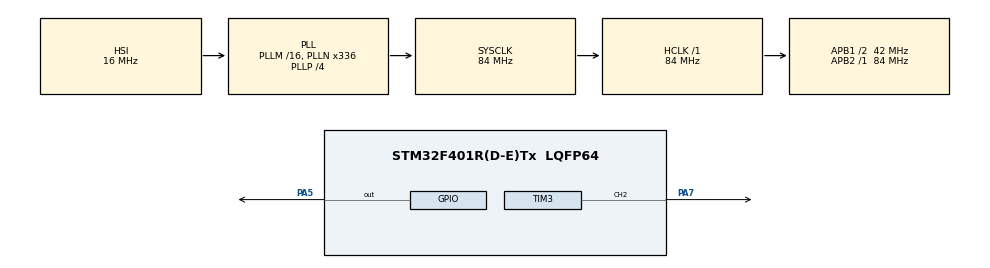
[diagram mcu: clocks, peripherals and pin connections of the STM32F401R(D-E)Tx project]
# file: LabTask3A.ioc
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Mcu.Family=STM32F4
Mcu.Name=STM32F401R(D-E)Tx
Mcu.Package=LQFP64
NVIC.PriorityGroup=NVIC_PRIORITYGROUP_4
NVIC.TIM3_IRQn=true\:0\:0\:false\:false\:true\:true\:true\:true
NVIC.TIM4_IRQn=true\:0\:0\:false\:false\:true\:true\:true\:true
PA5.Signal=GPIO_Output
PA7.Signal=S_TIM3_CH2
ProjectManager.HeapSize=0x200
ProjectManager.StackSize=0x400
ProjectManager.TargetToolchain=STM32CubeIDE
RCC.48MHZClocksFreq_Value=84000000
RCC.AHBFreq_Value=84000000
RCC.APB1CLKDivider=RCC_HCLK_DIV2
RCC.APB1Freq_Value=42000000
RCC.APB1TimFreq_Value=84000000
RCC.APB2Freq_Value=84000000
RCC.APB2TimFreq_Value=84000000
RCC.CortexFreq_Value=84000000
RCC.HCLKFreq_Value=84000000
RCC.HSE_VALUE=25000000
RCC.HSI_VALUE=16000000
RCC.LSE_VALUE=32768
RCC.PLLN=336
RCC.PLLP=RCC_PLLP_DIV4
RCC.SYSCLKFreq_VALUE=84000000
RCC.SYSCLKSource=RCC_SYSCLKSOURCE_PLLCLK
RCC.VCOOutputFreq_Value=336000000
SH.S_TIM3_CH2.0=TIM3_CH2,PWM Generation2 CH2
TIM3.AutoReloadPreload=TIM_AUTORELOAD_PRELOAD_ENABLE
TIM3.Channel-PWM\ Generation2\ CH2=TIM_CHANNEL_2
TIM3.Period=3821
TIM3.Prescaler=83
TIM3.Pulse-PWM\ Generation2\ CH2=1911
TIM4.Period=4999
TIM4.Prescaler=8399
VP_TIM3_VS_ClockSourceINT.Mode=Internal
VP_TIM4_VS_ClockSourceINT.Mode=Internal
board=custom

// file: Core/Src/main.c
/* USER CODE BEGIN Header */
/**
  ******************************************************************************
  * @file           : main.c
  * @brief          : Main program body
  ******************************************************************************
  * @attention
  *
  * Copyright (c) 2026 STMicroelectronics.
  * All rights reserved.
  *
  * This software is licensed under terms that can be found in the LICENSE file
  * in the root directory of this software component.
  * If no LICENSE file comes with this software, it is provided AS-IS.
  *
  ******************************************************************************
  */
/* USER CODE END Header */
#include "main.h"

TIM_HandleTypeDef htim3;
TIM_HandleTypeDef htim4;

/* USER CODE BEGIN PV */
uint32_t note_arr[] = {
    3821,   // C4
    3405,   // D4
    3032,   // E4
    2550    // G4
};

uint32_t duty_arr[] = {
    255,    // 10%
    1276,   // 50%
    2296    // 90%
};

volatile uint8_t note = 0;
volatile uint8_t duty = 0;
/* USER CODE END PV */

void SystemClock_Config(void);
static void MX_GPIO_Init(void);
static void MX_TIM3_Init(void);
static void MX_TIM4_Init(void);

int main(void)
{

  /* MCU Configuration--------------------------------------------------------*/

  /* Reset of all peripherals, Initializes the Flash interface and the Systick. */
  HAL_Init();

  /* Configure the system clock */
  SystemClock_Config();

  /* Initialize all configured peripherals */
  MX_GPIO_Init();
  MX_TIM3_Init();
  MX_TIM4_Init();
  /* USER CODE BEGIN 2 */

  HAL_TIM_PWM_Start(&htim3, TIM_CHANNEL_2);
  HAL_TIM_Base_Start_IT(&htim4);

  /* USER CODE END 2 */

  /* Infinite loop */
  while (1)
  {

  }
}

void SystemClock_Config(void)
{
  RCC_OscInitTypeDef RCC_OscInitStruct = {0};
  RCC_ClkInitTypeDef RCC_ClkInitStruct = {0};

  /** Configure the main internal regulator output voltage
  */
  __HAL_RCC_PWR_CLK_ENABLE();
  __HAL_PWR_VOLTAGESCALING_CONFIG(PWR_REGULATOR_VOLTAGE_SCALE2);

  /** Initializes the RCC Oscillators according to the specified parameters
  * in the RCC_OscInitTypeDef structure.
  */
  RCC_OscInitStruct.OscillatorType = RCC_OSCILLATORTYPE_HSI;
  RCC_OscInitStruct.HSIState = RCC_HSI_ON;
  RCC_OscInitStruct.HSICalibrationValue = RCC_HSICALIBRATION_DEFAULT;
  RCC_OscInitStruct.PLL.PLLState = RCC_PLL_ON;
  RCC_OscInitStruct.PLL.PLLSource = RCC_PLLSOURCE_HSI;
  RCC_OscInitStruct.PLL.PLLM = 16;
  RCC_OscInitStruct.PLL.PLLN = 336;
  RCC_OscInitStruct.PLL.PLLP = RCC_PLLP_DIV4;
  RCC_OscInitStruct.PLL.PLLQ = 4;
  if (HAL_RCC_OscConfig(&RCC_OscInitStruct) != HAL_OK)
  {
    Error_Handler();
  }

  /** Initializes the CPU, AHB and APB buses clocks
  */
  RCC_ClkInitStruct.ClockType = RCC_CLOCKTYPE_HCLK|RCC_CLOCKTYPE_SYSCLK
                              |RCC_CLOCKTYPE_PCLK1|RCC_CLOCKTYPE_PCLK2;
  RCC_ClkInitStruct.SYSCLKSource = RCC_SYSCLKSOURCE_PLLCLK;
  RCC_ClkInitStruct.AHBCLKDivider = RCC_SYSCLK_DIV1;
  RCC_ClkInitStruct.APB1CLKDivider = RCC_HCLK_DIV2;
  RCC_ClkInitStruct.APB2CLKDivider = RCC_HCLK_DIV1;

  if (HAL_RCC_ClockConfig(&RCC_ClkInitStruct, FLASH_LATENCY_2) != HAL_OK)
  {
    Error_Handler();
  }
}

static void MX_TIM3_Init(void)
{

  TIM_ClockConfigTypeDef sClockSourceConfig = {0};
  TIM_MasterConfigTypeDef sMasterConfig = {0};
  TIM_OC_InitTypeDef sConfigOC = {0};

  htim3.Instance = TIM3;
  htim3.Init.Prescaler = 83;
  htim3.Init.CounterMode = TIM_COUNTERMODE_UP;
  htim3.Init.Period = 3821;
  htim3.Init.ClockDivision = TIM_CLOCKDIVISION_DIV1;
  htim3.Init.AutoReloadPreload = TIM_AUTORELOAD_PRELOAD_ENABLE;
  if (HAL_TIM_Base_Init(&htim3) != HAL_OK)
  {
    Error_Handler();
  }
  sClockSourceConfig.ClockSource = TIM_CLOCKSOURCE_INTERNAL;
  if (HAL_TIM_ConfigClockSource(&htim3, &sClockSourceConfig) != HAL_OK)
  {
    Error_Handler();
  }
  if (HAL_TIM_PWM_Init(&htim3) != HAL_OK)
  {
    Error_Handler();
  }
  sMasterConfig.MasterOutputTrigger = TIM_TRGO_RESET;
  sMasterConfig.MasterSlaveMode = TIM_MASTERSLAVEMODE_DISABLE;
  if (HAL_TIMEx_MasterConfigSynchronization(&htim3, &sMasterConfig) != HAL_OK)
  {
    Error_Handler();
  }
  sConfigOC.OCMode = TIM_OCMODE_PWM1;
  sConfigOC.Pulse = 1911;
  sConfigOC.OCPolarity = TIM_OCPOLARITY_HIGH;
  sConfigOC.OCFastMode = TIM_OCFAST_DISABLE;
  if (HAL_TIM_PWM_ConfigChannel(&htim3, &sConfigOC, TIM_CHANNEL_2) != HAL_OK)
  {
    Error_Handler();
  }
  HAL_TIM_MspPostInit(&htim3);

}

static void MX_TIM4_Init(void)
{

  TIM_ClockConfigTypeDef sClockSourceConfig = {0};
  TIM_MasterConfigTypeDef sMasterConfig = {0};

  htim4.Instance = TIM4;
  htim4.Init.Prescaler = 8399;
  htim4.Init.CounterMode = TIM_COUNTERMODE_UP;
  htim4.Init.Period = 4999;
  htim4.Init.ClockDivision = TIM_CLOCKDIVISION_DIV1;
  htim4.Init.AutoReloadPreload = TIM_AUTORELOAD_PRELOAD_DISABLE;
  if (HAL_TIM_Base_Init(&htim4) != HAL_OK)
  {
    Error_Handler();
  }
  sClockSourceConfig.ClockSource = TIM_CLOCKSOURCE_INTERNAL;
  if (HAL_TIM_ConfigClockSource(&htim4, &sClockSourceConfig) != HAL_OK)
  {
    Error_Handler();
  }
  sMasterConfig.MasterOutputTrigger = TIM_TRGO_RESET;
  sMasterConfig.MasterSlaveMode = TIM_MASTERSLAVEMODE_DISABLE;
  if (HAL_TIMEx_MasterConfigSynchronization(&htim4, &sMasterConfig) != HAL_OK)
  {
    Error_Handler();
  }

}

static void MX_GPIO_Init(void)
{
  GPIO_InitTypeDef GPIO_InitStruct = {0};

  /* GPIO Ports Clock Enable */
  __HAL_RCC_GPIOA_CLK_ENABLE();

  /*Configure GPIO pin Output Level */
  HAL_GPIO_WritePin(GPIOA, GPIO_PIN_5, GPIO_PIN_RESET);

  /*Configure GPIO pin : PA5 */
  GPIO_InitStruct.Pin = GPIO_PIN_5;
  GPIO_InitStruct.Mode = GPIO_MODE_OUTPUT_PP;
  GPIO_InitStruct.Pull = GPIO_NOPULL;
  GPIO_InitStruct.Speed = GPIO_SPEED_FREQ_LOW;
  HAL_GPIO_Init(GPIOA, &GPIO_InitStruct);

}

/* USER CODE BEGIN 4 */

void HAL_TIM_PeriodElapsedCallback(TIM_HandleTypeDef *htim)
{
    if (htim->Instance == TIM4)
    {
    	if(note < 4) {
			uint32_t arr = note_arr[note];

			__HAL_TIM_SET_AUTORELOAD(&htim3, arr); // change ARR during update event
			__HAL_TIM_SET_COMPARE(&htim3, TIM_CHANNEL_2, (arr + 1) / 2); // 50% duty cycle

//			note++;
    	}

    	else{
    		uint32_t ccr = duty_arr[duty];
    		__HAL_TIM_SET_AUTORELOAD(&htim3, note_arr[3]); // ARR remains unchanged
    		__HAL_TIM_SET_COMPARE(&htim3, TIM_CHANNEL_2, ccr); // CCR changes accordingly to Duty cycle

    		duty = (duty + 1) % 3;
    	}
    }
}

/* USER CODE END 4 */

void Error_Handler(void)
{
  __disable_irq();
  while (1)
  {
  }
}
